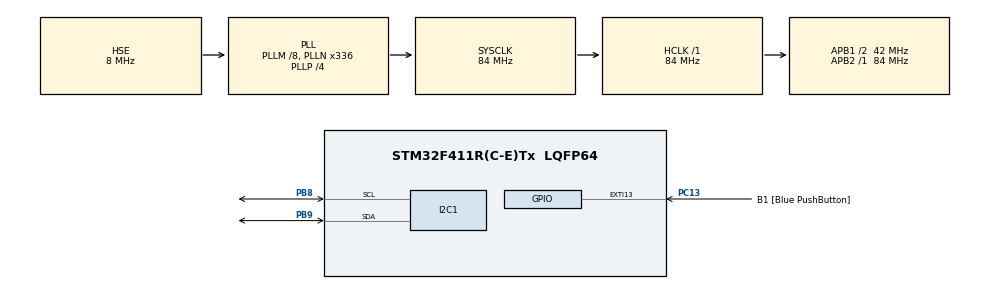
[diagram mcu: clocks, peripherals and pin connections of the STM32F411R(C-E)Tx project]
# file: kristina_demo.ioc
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Mcu.Family=STM32F4
Mcu.Name=STM32F411R(C-E)Tx
Mcu.Package=LQFP64
NVIC.PriorityGroup=NVIC_PRIORITYGROUP_0
PA13.GPIO_Label=TMS
PA13.Mode=Trace_Asynchronous_SW
PA13.Signal=SYS_JTMS-SWDIO
PA14.GPIO_Label=TCK
PA14.Mode=Trace_Asynchronous_SW
PA14.Signal=SYS_JTCK-SWCLK
PB3.GPIO_Label=SWO
PB3.Mode=Trace_Asynchronous_SW
PB3.Signal=SYS_JTDO-SWO
PB8.Mode=I2C
PB8.Signal=I2C1_SCL
PB9.Mode=I2C
PB9.Signal=I2C1_SDA
PC13-ANTI_TAMP.GPIO_Label=B1 [Blue PushButton]
PC13-ANTI_TAMP.GPIO_ModeDefaultEXTI=GPIO_MODE_IT_FALLING
PC13-ANTI_TAMP.Signal=GPXTI13
PC14-OSC32_IN.Mode=LSE-External-Oscillator
PC14-OSC32_IN.Signal=RCC_OSC32_IN
PC15-OSC32_OUT.Mode=LSE-External-Oscillator
PC15-OSC32_OUT.Signal=RCC_OSC32_OUT
PH0\ -\ OSC_IN.Mode=HSE-External-Clock-Source
PH0\ -\ OSC_IN.Signal=RCC_OSC_IN
PH1\ -\ OSC_OUT.Mode=HSE-External-Clock-Source
PH1\ -\ OSC_OUT.Signal=RCC_OSC_OUT
ProjectManager.HeapSize=0x200
ProjectManager.StackSize=0x400
ProjectManager.TargetToolchain=STM32CubeIDE
RCC.48MHZClocksFreq_Value=84000000
RCC.AHBFreq_Value=84000000
RCC.APB1CLKDivider=RCC_HCLK_DIV2
RCC.APB1Freq_Value=42000000
RCC.APB1TimFreq_Value=84000000
RCC.APB2Freq_Value=84000000
RCC.APB2TimFreq_Value=84000000
RCC.CortexFreq_Value=84000000
RCC.FLatency-AdvancedSettings=FLASH_LATENCY_2
RCC.HCLKFreq_Value=84000000
RCC.HSE_VALUE=8000000
RCC.HSI_VALUE=16000000
RCC.PLLM=8
RCC.PLLN=336
RCC.PLLP=RCC_PLLP_DIV4
RCC.PLLSourceVirtual=RCC_PLLSOURCE_HSE
RCC.SYSCLKFreq_VALUE=84000000
RCC.SYSCLKSource=RCC_SYSCLKSOURCE_PLLCLK
RCC.VCOOutputFreq_Value=336000000
board=NUCLEO-F411RE

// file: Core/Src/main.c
/* USER CODE BEGIN Header */
/**
  ******************************************************************************
  * @file           : main.c
  * @brief          : Main program body
  ******************************************************************************
  * @attention
  *
  * Copyright (c) 2024 STMicroelectronics.
  * All rights reserved.
  *
  * This software is licensed under terms that can be found in the LICENSE file
  * in the root directory of this software component.
  * If no LICENSE file comes with this software, it is provided AS-IS.
  *
  ******************************************************************************
  */
/* USER CODE END Header */
#include "main.h"

/* USER CODE BEGIN Includes */
#include <stdio.h>
#include "ADC.h"
#include "BMP180_Driver.h"
#include "DHT11_Driver.h"
#include "GPIO.h"
#include "I2C.h"
#include "JR_Driver.h"
#include "LCD1602_Driver.h"
#include "LED_Driver.h"
#include "OLED_Driver.h"
#include "OLED_Font.h"
#include "RTC_Driver.h"
#include "Servo.h"
#include "timer_delay.h"

volatile uint32_t timer_counter = 0;
volatile uint32_t tick_counter = 0;

int _write(int file, char *ptr, int len) {
	int i=0;
	for (i=0;i<len;i++)
		ITM_SendChar((*ptr++));
	return len;
}

const unsigned char bstu[] = {0xff, 0xff, 0xff, 0xff, 0xff, 0xff, 0xff, 0xff, 0xff, 0xff, 0xff, 0xff, 0xff, 0xff, 0xff, 0xff,
		0xff, 0xff, 0xff, 0xff, 0xff, 0xff, 0xff, 0xff, 0xff, 0xff, 0xff, 0xff, 0xff, 0xff, 0xff, 0xff,
		0xff, 0xff, 0xff, 0xff, 0xff, 0xff, 0xff, 0xff, 0xff, 0xff, 0xff, 0xff, 0xff, 0xff, 0xff, 0xff,
		0xff, 0xff, 0xff, 0xff, 0xff, 0xff, 0xff, 0xff, 0xff, 0xff, 0xff, 0xff, 0xff, 0xff, 0xff, 0xff,
		0xff, 0xff, 0xff, 0xff, 0xff, 0xff, 0xff, 0xff, 0xff, 0xff, 0xff, 0xff, 0xff, 0xff, 0xff, 0xfe,
		0xff, 0xff, 0xff, 0xff, 0xff, 0xff, 0xff, 0xff, 0xff, 0xff, 0xff, 0xff, 0xff, 0xff, 0xff, 0xfe,
		0xff, 0xff, 0xff, 0xff, 0xff, 0xff, 0xff, 0xff, 0xff, 0xff, 0xff, 0xff, 0xff, 0xff, 0xff, 0xff,
		0xff, 0xff, 0xff, 0xff, 0xff, 0xff, 0xff, 0xff, 0xff, 0xff, 0xff, 0xff, 0xff, 0xff, 0xff, 0xff,
		0xff, 0xff, 0xff, 0xff, 0xff, 0xff, 0xff, 0xff, 0xff, 0xff, 0xff, 0xff, 0xff, 0xff, 0xff, 0xef,
		0xff, 0xff, 0xff, 0xff, 0xff, 0xff, 0xff, 0xff, 0xff, 0xff, 0xff, 0xff, 0xff, 0xff, 0xff, 0xff,
		0xff, 0xff, 0xfe, 0x00, 0x03, 0xf8, 0x00, 0x0f, 0x80, 0x00, 0x3e, 0x07, 0xc0, 0xff, 0xff, 0xff,
		0xff, 0xff, 0xfe, 0x00, 0x03, 0xf8, 0x00, 0x07, 0x80, 0x00, 0x3c, 0x03, 0x80, 0x7f, 0xff, 0xff,
		0xff, 0xff, 0xfe, 0x00, 0x03, 0xf8, 0x00, 0x07, 0x80, 0x00, 0x3c, 0x07, 0xc0, 0x7f, 0xff, 0xfe,
		0xff, 0xff, 0xff, 0x03, 0xc3, 0xfc, 0x1f, 0x87, 0x8e, 0x0c, 0x3e, 0x07, 0xc0, 0xff, 0xff, 0xfe,
		0xff, 0xff, 0xff, 0x87, 0xe3, 0xfc, 0x1f, 0xc7, 0x8e, 0x0e, 0x3f, 0x07, 0xe1, 0xff, 0xff, 0xff,
		0xff, 0xff, 0xff, 0x87, 0xff, 0xfe, 0x1f, 0xc7, 0x8e, 0x0e, 0x3f, 0x87, 0xc3, 0xff, 0xff, 0xff,
		0xff, 0xff, 0xff, 0x87, 0xff, 0xfe, 0x1f, 0xff, 0xde, 0x0f, 0x7f, 0x87, 0xc3, 0xff, 0xff, 0xff,
		0xff, 0xff, 0xff, 0x87, 0xff, 0xfe, 0x1f, 0xff, 0xfe, 0x0f, 0xff, 0xc3, 0xc3, 0xff, 0xff, 0xff,
		0xff, 0xff, 0xff, 0x80, 0x0f, 0xfe, 0x1f, 0xff, 0xfe, 0x0f, 0xff, 0xc3, 0x87, 0xff, 0xff, 0xff,
		0xff, 0xff, 0xff, 0x80, 0x03, 0xfe, 0x1f, 0xff, 0xfe, 0x0f, 0xff, 0xe1, 0x87, 0xff, 0xff, 0xff,
		0xff, 0xff, 0xff, 0x80, 0x01, 0xfe, 0x1f, 0xff, 0xfe, 0x0f, 0xff, 0xe1, 0x0f, 0xff, 0xff, 0xfe,
		0xff, 0xff, 0xff, 0x87, 0xc0, 0xfe, 0x1f, 0xff, 0xfe, 0x0f, 0xff, 0xf0, 0x0f, 0xff, 0xff, 0xfe,
		0xff, 0xff, 0xff, 0x87, 0xe0, 0xfe, 0x1f, 0xff, 0xfe, 0x0f, 0xff, 0xf0, 0x1f, 0xff, 0xff, 0xff,
		0xff, 0xff, 0xff, 0x87, 0xf0, 0xfe, 0x1f, 0xff, 0xfe, 0x0f, 0xff, 0xf8, 0x1f, 0xff, 0xff, 0xff,
		0xff, 0xff, 0xff, 0x87, 0xf0, 0xfe, 0x1f, 0xff, 0xfe, 0x0f, 0xff, 0xf8, 0x1f, 0xff, 0xff, 0xff,
		0xff, 0xff, 0xff, 0x87, 0xe0, 0xfe, 0x1f, 0xff, 0xfe, 0x0f, 0xff, 0xfc, 0x3f, 0xff, 0xff, 0xff,
		0xff, 0xff, 0xff, 0x07, 0xe0, 0xfc, 0x1f, 0xff, 0xfe, 0x0f, 0xff, 0xf8, 0x3f, 0xff, 0xff, 0xff,
		0xff, 0xff, 0xfe, 0x00, 0x01, 0xf8, 0x07, 0xff, 0xfc, 0x07, 0xff, 0xc0, 0x7f, 0xff, 0xff, 0xff,
		0xff, 0xff, 0xfe, 0x00, 0x03, 0xf8, 0x03, 0xff, 0xf8, 0x03, 0xff, 0x80, 0x7f, 0xff, 0xff, 0xff,
		0xff, 0xff, 0xfe, 0x00, 0x07, 0xf8, 0x07, 0xff, 0xf8, 0x03, 0xff, 0x80, 0xff, 0xff, 0xff, 0xff,
		0xff, 0xff, 0xff, 0xff, 0xff, 0xff, 0xff, 0xff, 0xff, 0xff, 0xff, 0xf3, 0xff, 0xff, 0xff, 0xff,
		0xff, 0xff, 0xff, 0xff, 0xff, 0xff, 0xff, 0xff, 0xff, 0xff, 0xff, 0xff, 0xff, 0xff, 0xff, 0xff,
		0xff, 0xff, 0xff, 0xff, 0xff, 0xff, 0xff, 0xff, 0xff, 0xff, 0xff, 0xff, 0xff, 0xff, 0xff, 0xff,
		0xff, 0xff, 0xff, 0xff, 0xff, 0xff, 0xff, 0xff, 0xff, 0xff, 0xff, 0xff, 0xff, 0xff, 0xff, 0xff,
		0xff, 0xff, 0xff, 0xff, 0xff, 0xff, 0xff, 0xff, 0xff, 0xff, 0xff, 0xff, 0xff, 0xff, 0xff, 0xff,
		0xff, 0xff, 0xff, 0xff, 0xff, 0xff, 0xff, 0xff, 0x99, 0x9f, 0xff, 0xff, 0xff, 0xff, 0xff, 0xff,
		0xff, 0xff, 0xff, 0xff, 0xff, 0xff, 0xff, 0xff, 0x9b, 0xbf, 0xff, 0xff, 0xff, 0xff, 0xff, 0xff,
		0xff, 0xff, 0xfe, 0xec, 0xf3, 0x1b, 0xb7, 0x7f, 0x9b, 0xb6, 0x19, 0x8c, 0x38, 0xff, 0xff, 0xff,
		0xff, 0xff, 0xfe, 0x44, 0x62, 0x49, 0xb2, 0x7f, 0x9b, 0xb6, 0x61, 0x24, 0x9c, 0xff, 0xff, 0xff,
		0xff, 0xff, 0xfe, 0x46, 0x66, 0x59, 0x32, 0x7f, 0x9b, 0xba, 0x63, 0x76, 0x9f, 0xff, 0xff, 0xff,
		0xff, 0xff, 0xfe, 0x26, 0x06, 0x19, 0x31, 0x7f, 0x9b, 0xba, 0xe3, 0x76, 0x96, 0xff, 0xff, 0xff,
		0xff, 0xff, 0xfe, 0x26, 0x96, 0x7b, 0xb3, 0x7f, 0x9b, 0xb8, 0xe3, 0x36, 0xd6, 0x7f, 0xff, 0xff,
		0xff, 0xff, 0xff, 0x76, 0xf3, 0x1b, 0x93, 0x3f, 0x91, 0x3c, 0xc1, 0x8c, 0xb3, 0xff, 0xff, 0xff,
		0xff, 0xff, 0xff, 0xff, 0xff, 0xff, 0xff, 0xff, 0xff, 0xfd, 0xff, 0xff, 0xff, 0xff, 0xff, 0xff,
		0xff, 0xff, 0xff, 0xff, 0xff, 0xff, 0xff, 0xff, 0xff, 0xfd, 0xff, 0xff, 0xff, 0xff, 0xff, 0xff,
		0xff, 0xff, 0xff, 0xff, 0xff, 0xff, 0xff, 0xff, 0xff, 0xfb, 0xff, 0xff, 0xff, 0xff, 0xff, 0xff,
		0xff, 0xff, 0xff, 0xff, 0xff, 0xff, 0xff, 0xff, 0xff, 0xff, 0xff, 0xff, 0xff, 0xff, 0xff, 0xff,
		0xff, 0xff, 0xff, 0xff, 0xff, 0xff, 0xff, 0xff, 0xff, 0xff, 0xff, 0xff, 0xff, 0xff, 0xff, 0xff,
		0xff, 0xff, 0xff, 0xff, 0xff, 0xff, 0xff, 0xff, 0xff, 0xff, 0xff, 0xff, 0xff, 0xff, 0xff, 0xff,
		0xff, 0xff, 0xff, 0xff, 0xff, 0xff, 0xff, 0xff, 0xff, 0xff, 0xff, 0xff, 0xff, 0xff, 0xff, 0xff,
		0xff, 0xff, 0xff, 0xff, 0xff, 0xff, 0xff, 0xff, 0xff, 0xff, 0xff, 0xff, 0xff, 0xff, 0xff, 0xff,
		0xff, 0xff, 0xff, 0xff, 0xff, 0xff, 0xff, 0xff, 0xff, 0xff, 0xff, 0xff, 0xff, 0xff, 0xff, 0xff,
		0xff, 0xff, 0xff, 0xff, 0xff, 0xff, 0xff, 0xff, 0xff, 0xff, 0xff, 0xff, 0xff, 0xff, 0xff, 0xff,
		0xff, 0xff, 0xff, 0xff, 0xff, 0xff, 0xff, 0xff, 0xff, 0xff, 0xff, 0xff, 0xff, 0xff, 0xff, 0xff,
		0xff, 0xff, 0xff, 0xff, 0xff, 0xff, 0xff, 0xff, 0xff, 0xff, 0xff, 0xff, 0xff, 0xff, 0xff, 0xff,
		0xff, 0xff, 0xff, 0xff, 0xff, 0xff, 0xff, 0xff, 0xff, 0xff, 0xff, 0xff, 0xff, 0xff, 0xff, 0xff,
		0xff, 0xff, 0xff, 0xff, 0xff, 0xff, 0xff, 0xff, 0xff, 0xff, 0xff, 0xff, 0xff, 0xff, 0xff, 0xff,
		0xff, 0xff, 0xff, 0xff, 0xff, 0xff, 0xff, 0xff, 0xff, 0xff, 0xff, 0xff, 0xff, 0xff, 0xff, 0xff,
		0xff, 0xff, 0xff, 0xff, 0xff, 0xff, 0xff, 0xff, 0xff, 0xff, 0xff, 0xff, 0xff, 0xff, 0xff, 0xff,
		0xff, 0xff, 0xff, 0xff, 0xff, 0xff, 0xff, 0xff, 0xff, 0xff, 0xff, 0xff, 0xff, 0xff, 0xff, 0xff,
		0xff, 0xff, 0xff, 0xff, 0xff, 0xff, 0xff, 0xff, 0xff, 0xff, 0xff, 0xfc, 0x00, 0x00, 0xff, 0xff,
		0xff, 0xff, 0xff, 0xff, 0xff, 0xff, 0xff, 0xff, 0xff, 0xff, 0xe0, 0x00, 0x00, 0x03, 0xff, 0xff,
		0xff, 0xff, 0xff, 0xff, 0xff, 0xff, 0xff, 0xff, 0xff, 0xc0, 0x00, 0x00, 0x00, 0x07, 0xff, 0xff,
		0xff, 0xff, 0xff, 0xff, 0xff, 0xff, 0xff, 0xfe, 0x00, 0x00, 0x31, 0x88, 0x03, 0x27, 0xff, 0xff};

/* USER CODE END Includes */

I2C_HandleTypeDef hi2c1;

void SystemClock_Config(void);
static void MX_GPIO_Init(void);
static void MX_I2C1_Init(void);

int main(void)
{

  /* MCU Configuration--------------------------------------------------------*/

  /* Reset of all peripherals, Initializes the Flash interface and the Systick. */
  HAL_Init();

  /* Configure the system clock */
  SystemClock_Config();

  /* Initialize all configured peripherals */
  MX_GPIO_Init();
  MX_I2C1_Init();
  /* USER CODE BEGIN 2 */
  uint16_t coords[2] = {0};
  printf("Start program.\r\n");
  GPIO_Full_Init();
  //I2C_Init();
  I2C_Scan();
  Delay_Init();
  LCD_Init();
  ADC_Init();
  LED_Init();
  OLED_Init();
  Servo_Init();

  BMP_ReadCalibration();

  LCD_Print("Hello!");
  delay_us(1000000);

  tick_counter = 0;
  int j_on = 1;
  uint8_t rtc_data[7] = {0};
  /* USER CODE END 2 */

  /* Infinite loop */
  /* USER CODE BEGIN WHILE */
  while (1)
  {
	  //Режим работы (битмап или джойстик)
	  if (j_on) {
	  //Джостик и OLED
	  Joystick_getCoords(coords);
	  OLED_Fill(0);
	  OLED_DrawRectangle(32, 0, 95, 63);
	  float j_x = coords[0]/4096.0*62.0+32;
	  float j_y = coords[1]/4096.0*62.0;
	  OLED_DrawPixel((int)j_x,(int)j_y, 1);
	  OLED_Update();
	  }
	  //Регулятор и индикатор
	  uint8_t vlm_v = Regulator_getValue()/4096.0*10.0;
	  LED_Volume_Set(0b1111111111 >> vlm_v);
	  uint8_t srv_v = Regulator_getValue()/4096.0 * 180.0;
	  Servo_Set(srv_v);
	  //Вывод DHT и BMP (темп влаж темп давл)
	  if (tick_counter == 0) {
		  float dht_data[2] = {0};
		  DHT_Get(dht_data);
		  float bmp_temp = BMP_GetTemp();
		  long bmp_pres = BMP_GetPressure();
		  long bmp_alt = BMP_GetAltitude();
		  delay_us(1000);//гложит шину..
		  RTC_Read(rtc_data);
		  char lcd_msg[17];
		  snprintf(lcd_msg, sizeof(lcd_msg), "%02d:%02d %2.1f %d", rtc_data[2], rtc_data[1], bmp_temp, bmp_pres);
		  LCD_Clear();
		  LCD_Print(lcd_msg);
		  snprintf(lcd_msg, sizeof(lcd_msg), "DHT: %-2.0f %-2.0f%%", dht_data[0], dht_data[1]);
		  LCD_SetCursor(1, 0);
		  LCD_Print(lcd_msg);
		  snprintf(lcd_msg, sizeof(lcd_msg), "%3ldm\0", bmp_alt);
		  LCD_SetCursor(1, 12);
		  LCD_Print(lcd_msg);

		  tick_counter = 2000;
		  //timer_counter = 2000;
	  }
	  //Если джойстик нажат
	  if (!READ_BIT(GPIOA->IDR, GPIO_IDR_ID5_Msk)) {
		  //RTC_Set(9, 14, 00, 21, 6, 24);
		  if (j_on) {
			 j_on = 0;
			 OLED_Fill(0);
		  OLED_DrawBitmap(bstu, 0, 0, 128, 64);
		  OLED_Update();
		  }
		  else {
			  j_on = 1;		  }
	  }
	  delay_us(10000);
	  //printf("%ld\r\n", Mic_getValue());
    /* USER CODE END WHILE */

  }
}

void SystemClock_Config(void)
{
  RCC_OscInitTypeDef RCC_OscInitStruct = {0};
  RCC_ClkInitTypeDef RCC_ClkInitStruct = {0};

  /** Configure the main internal regulator output voltage
  */
  __HAL_RCC_PWR_CLK_ENABLE();
  __HAL_PWR_VOLTAGESCALING_CONFIG(PWR_REGULATOR_VOLTAGE_SCALE1);

  /** Initializes the RCC Oscillators according to the specified parameters
  * in the RCC_OscInitTypeDef structure.
  */
  RCC_OscInitStruct.OscillatorType = RCC_OSCILLATORTYPE_HSE;
  RCC_OscInitStruct.HSEState = RCC_HSE_BYPASS;
  RCC_OscInitStruct.PLL.PLLState = RCC_PLL_ON;
  RCC_OscInitStruct.PLL.PLLSource = RCC_PLLSOURCE_HSE;
  RCC_OscInitStruct.PLL.PLLM = 8;
  RCC_OscInitStruct.PLL.PLLN = 336;
  RCC_OscInitStruct.PLL.PLLP = RCC_PLLP_DIV4;
  RCC_OscInitStruct.PLL.PLLQ = 4;
  if (HAL_RCC_OscConfig(&RCC_OscInitStruct) != HAL_OK)
  {
    Error_Handler();
  }

  /** Initializes the CPU, AHB and APB buses clocks
  */
  RCC_ClkInitStruct.ClockType = RCC_CLOCKTYPE_HCLK|RCC_CLOCKTYPE_SYSCLK
                              |RCC_CLOCKTYPE_PCLK1|RCC_CLOCKTYPE_PCLK2;
  RCC_ClkInitStruct.SYSCLKSource = RCC_SYSCLKSOURCE_PLLCLK;
  RCC_ClkInitStruct.AHBCLKDivider = RCC_SYSCLK_DIV1;
  RCC_ClkInitStruct.APB1CLKDivider = RCC_HCLK_DIV2;
  RCC_ClkInitStruct.APB2CLKDivider = RCC_HCLK_DIV1;

  if (HAL_RCC_ClockConfig(&RCC_ClkInitStruct, FLASH_LATENCY_2) != HAL_OK)
  {
    Error_Handler();
  }
}

static void MX_I2C1_Init(void)
{

  hi2c1.Instance = I2C1;
  hi2c1.Init.ClockSpeed = 100000;
  hi2c1.Init.DutyCycle = I2C_DUTYCYCLE_2;
  hi2c1.Init.OwnAddress1 = 0;
  hi2c1.Init.AddressingMode = I2C_ADDRESSINGMODE_7BIT;
  hi2c1.Init.DualAddressMode = I2C_DUALADDRESS_DISABLE;
  hi2c1.Init.OwnAddress2 = 0;
  hi2c1.Init.GeneralCallMode = I2C_GENERALCALL_DISABLE;
  hi2c1.Init.NoStretchMode = I2C_NOSTRETCH_DISABLE;
  if (HAL_I2C_Init(&hi2c1) != HAL_OK)
  {
    Error_Handler();
  }

}

static void MX_GPIO_Init(void)
{
  GPIO_InitTypeDef GPIO_InitStruct = {0};

  /* GPIO Ports Clock Enable */
  __HAL_RCC_GPIOC_CLK_ENABLE();
  __HAL_RCC_GPIOH_CLK_ENABLE();
  __HAL_RCC_GPIOA_CLK_ENABLE();
  __HAL_RCC_GPIOB_CLK_ENABLE();

  /*Configure GPIO pin : B1_Pin */
  GPIO_InitStruct.Pin = B1_Pin;
  GPIO_InitStruct.Mode = GPIO_MODE_IT_FALLING;
  GPIO_InitStruct.Pull = GPIO_NOPULL;
  HAL_GPIO_Init(B1_GPIO_Port, &GPIO_InitStruct);

}

void Error_Handler(void)
{
  __disable_irq();
  while (1)
  {
  }
}
